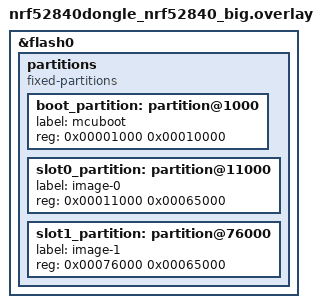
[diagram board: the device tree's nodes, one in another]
/*
 * Copyright (c) 2026 Tolt Technologies
 *
 * SPDX-License-Identifier: Apache-2.0
 */

/delete-node/ &boot_partition;
/delete-node/ &slot0_partition;
/delete-node/ &slot1_partition;

&flash0 {
	partitions {
		compatible = "fixed-partitions";
		#address-cells = <1>;
		#size-cells = <1>;

		boot_partition: partition@1000 {
			label = "mcuboot";
			reg = <0x00001000 0x00010000>;
		};

		slot0_partition: partition@11000 {
			label = "image-0";
			reg = <0x00011000 0x00065000>;
		};

		slot1_partition: partition@76000 {
			label = "image-1";
			reg = <0x00076000 0x00065000>;
		};
	};
};
